# nrf5002 register map
Vendor: Nordic Semiconductor; Series: nRF50; File version: 1
CPU: CM0 r0p4, little endian, no MPU, no FPU, 2 interrupt priority bits, 32 interrupts
Registers are 32-bit, read-write, reset 0x0 unless marked. A register's access mark holds for its fields unless they carry their own. Offsets are from the block's base; [hi:lo] are bit positions; lines under a group give offsets from that group; {n}, {i} and the like mark numbered series.

## FICR — Factory Information Configuration Registers
Base 0x10000000
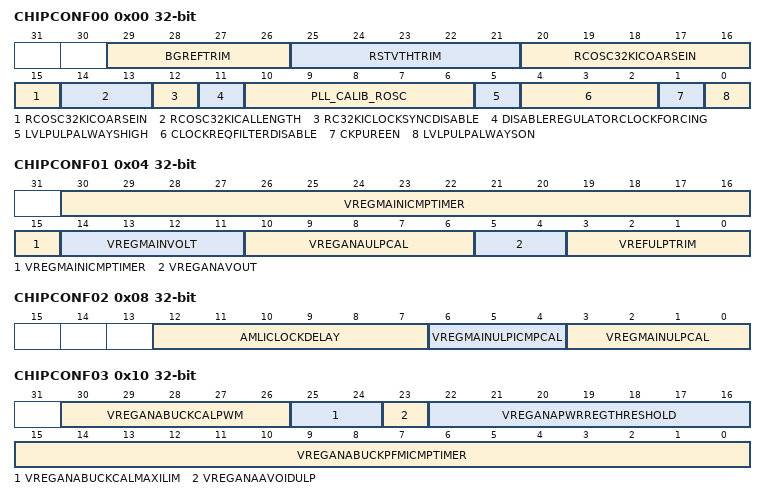
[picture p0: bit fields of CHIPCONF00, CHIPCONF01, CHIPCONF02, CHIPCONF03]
0x00 CHIPCONF00 — Unspecified
  [29:26] BGREFTRIM — Master bias bandgap trim
  [25:21] RSTVTHTRIM — Threshold trim, power on reset
  [20:15] RCOSC32KICOARSEIN — RCOSC coarse calibration input
  [14:13] RCOSC32KICALLENGTH — 32kHz RC oscillator calibration length in number of cycles
    0=N64 (64 cycles); 1=N128 (128 cycles); 2=N256 (256 cycles); 3=N512 (512 cycles)
  [12] RC32KICLOCKSYNCDISABLE — Disable synchronizer on calibration clock request from Rc32kiGenerator.
  [11] DISABLEREGULATORCLOCKFORCING
  [10:6] PLL_CALIB_ROSC — HFCLK ring oscillator trim codes. Previous name: HFROSCTRIM.
  [5] LVLPULPALWAYSHIGH — Control the output voltage for LVLP
  [4:2] CLOCKREQFILTERDISABLE — Disable glitch-filter on clock sources powerup and standby lines
    1=XOSC32M (Disable glitch-filter on powerUp- and standby lines to XOSC32M); 2=32ki (Disable glitch-filter on powerUp line to Rosc/Xosc/Synth used in clock system A (32ki)); 4=64M (Disable glitch-filter on powerUp line to PLL used in clock system B (64M))
  [1] CKPUREEN — Enable clock gate in clock purifier. Should always be 1.
  [0] LVLPULPALWAYSON — Force LVLP ULP regulators to be always on
0x04 CHIPCONF01 — Unspecified
  [30:15] VREGMAINICMPTIMER — Control the stay-alive time for VDD2 current comparator
  [14:11] VREGMAINVOLT — Control the output voltage for VREGMAIN
  [10:6] VREGANAULPCAL — VREGANA ULP output voltage calibration
    8=MIN (Min voltage); 0=DEF (Default voltage); 7=MAX (Max voltage)
  [5:4] VREGANAVOUT — Control the output voltage for VREGRADIO (AVDD_1V3)
  [3:0] VREFULPTRIM — RST low power voltage reference trim
0x08 CHIPCONF02 — Unspecified
  [12:7] AMLICLOCKDELAY — Trim value for AMLI clock delay
  [6:4] VREGMAINULPICMPCAL — Calibration of current comparator on VREGMAIN
  [3:0] VREGMAINULPCAL — Calibration of ULP regulator on VREGMAIN
0x10 CHIPCONF03 — Unspecified
  [30:26] VREGANABUCKCALPWM
  [25:24] VREGANABUCKCALMAXILIM
  [23] VREGANAAVOIDULP — Avoid ULP mode for VREGANA
    0=Default (Use default behavior); 1=AvoidUlp (Avoid using ULP)
  [22:16] VREGANAPWRREGTHRESHOLD — Regulator threshold for VREGANA
  [15:0] VREGANABUCKPFMICMPTIMER — Control the stay-alive time for the VREGANA PFM current comparator
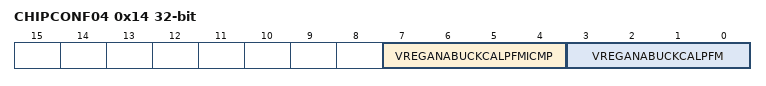
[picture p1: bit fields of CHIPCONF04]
0x14 CHIPCONF04 — Unspecified
  [7:4] VREGANABUCKCALPFMICMP, [3:0] VREGANABUCKCALPFM
0x130 SOCINFO group — Unspecified
  0x00 PARTNO ro reset 0x15 — Part number of the device.
    [31:0] PARTNO
      20=nRF5001 (Dagger52); 21=nRF5002 (Shoto); 0xFFFFFFFF=Unspecified
  0x04 HWREVISION ro reset 0xFFFFFFFF — Hardware Revision of the device. Will be updated in production test.
    [31:0] HWREVISION
      0=Rev1 (Unspecified)
  0x08 PRODUCTIONREVISION ro reset 0xFFFFFFFF — Production revision of the device. Will be updated in production test.
0x200 INFO group — Device info
  0x00 CONFIGID ro reset 0xFFFFFFFF — Configuration identifier
    [15:0] HWID — Identification number for the HW
  {0x4+4j} DEVICEID[{j}] (j=0..1) ro reset 0xFFFFFFFF — Description collection: Device identifier
    [31:0] DEVICEID — 64 bit unique device identifier
  0x0C PART ro reset 0xFFFFFFFF — Part code
    [31:0] PART
      0xFFFFFFFF=Unspecified
  0x10 VARIANT ro reset 0xFFFFFFFF — Part Variant, Hardware version and Production configuration
    [31:0] VARIANT — Part Variant, Hardware version and Production configuration, encoded as ASCII
      0xFFFFFFFF=Unspecified
  0x14 PACKAGE ro reset 0xFFFFFFFF — Package option
    [31:0] PACKAGE
      0xFFFFFFFF=Unspecified
  0x18 RAM ro reset 0xFFFFFFFF — RAM variant
    [31:0] RAM
      8=K8 (8 kByte RAM); 0xFFFFFFFF=Unspecified
  0x1C MTP ro reset 0xFFFFFFFF — MTP variant
    [31:0] MTP
      92=K92 (92 kByte NVM); 0xFFFFFFFF=Unspecified
  0x20 CODEPAGESIZE ro reset 0x800 — Code memory page size in bytes
    [31:0] CODEPAGESIZE
      0x800=K2048 (2 kByte); 0xFFFFFFFF=Unspecified
  0x24 CODESIZE ro reset 0x2E — Code memory size
    [31:0] CODESIZE — Code memory size in number of pages
      46=P46 (46 pages); 0xFFFFFFFF=Unspecified
  0x28 DEVICETYPE ro
    [31:0] DEVICETYPE
      0=Die (Device is an physical DIE); 0xFFFFFFFF=FPGA (Device is an FPGA)
